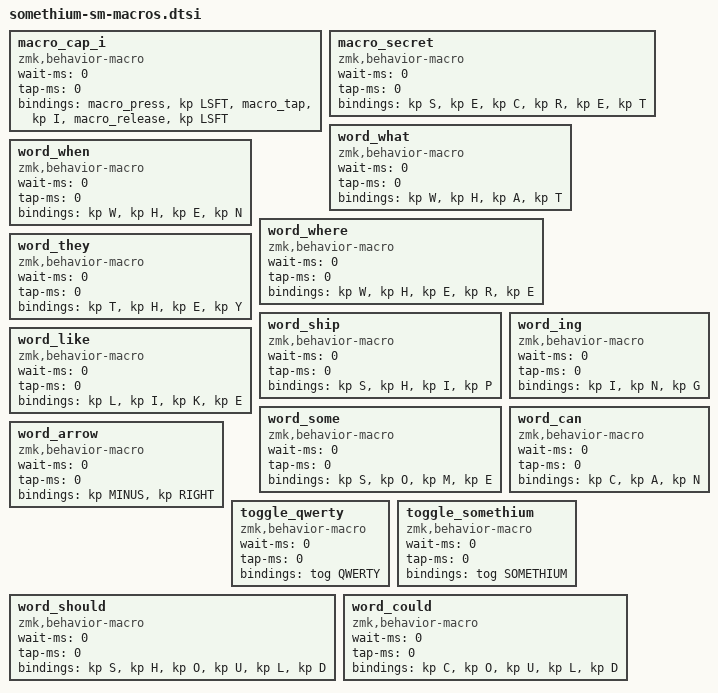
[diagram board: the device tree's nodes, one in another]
/*
 * Somethium word/toggle macros (included in main macros { }).
 */

        macro_cap_i: macro_cap_i {
            compatible = "zmk,behavior-macro";
            #binding-cells = <0>;
            wait-ms = <0>;
            tap-ms = <0>;
            bindings
                = <&macro_press &kp LSFT>
                , <&macro_tap &kp I>
                , <&macro_release &kp LSFT>
                ;
        };

        macro_secret: macro_secret {
            compatible = "zmk,behavior-macro";
            #binding-cells = <0>;
            wait-ms = <0>;
            tap-ms = <0>;
            bindings = <&kp S &kp E &kp C &kp R &kp E &kp T>;
        };

        word_what: word_what {
            compatible = "zmk,behavior-macro";
            #binding-cells = <0>;
            wait-ms = <0>;
            tap-ms = <0>;
            bindings = <&kp W &kp H &kp A &kp T>;
        };

        word_when: word_when {
            compatible = "zmk,behavior-macro";
            #binding-cells = <0>;
            wait-ms = <0>;
            tap-ms = <0>;
            bindings = <&kp W &kp H &kp E &kp N>;
        };

        word_where: word_where {
            compatible = "zmk,behavior-macro";
            #binding-cells = <0>;
            wait-ms = <0>;
            tap-ms = <0>;
            bindings = <&kp W &kp H &kp E &kp R &kp E>;
        };

        word_they: word_they {
            compatible = "zmk,behavior-macro";
            #binding-cells = <0>;
            wait-ms = <0>;
            tap-ms = <0>;
            bindings = <&kp T &kp H &kp E &kp Y>;
        };

        word_ship: word_ship {
            compatible = "zmk,behavior-macro";
            #binding-cells = <0>;
            wait-ms = <0>;
            tap-ms = <0>;
            bindings = <&kp S &kp H &kp I &kp P>;
        };

        word_ing: word_ing {
            compatible = "zmk,behavior-macro";
            #binding-cells = <0>;
            wait-ms = <0>;
            tap-ms = <0>;
            bindings = <&kp I &kp N &kp G>;
        };

        word_like: word_like {
            compatible = "zmk,behavior-macro";
            #binding-cells = <0>;
            wait-ms = <0>;
            tap-ms = <0>;
            bindings = <&kp L &kp I &kp K &kp E>;
        };

        word_some: word_some {
            compatible = "zmk,behavior-macro";
            #binding-cells = <0>;
            wait-ms = <0>;
            tap-ms = <0>;
            bindings = <&kp S &kp O &kp M &kp E>;
        };

        word_can: word_can {
            compatible = "zmk,behavior-macro";
            #binding-cells = <0>;
            wait-ms = <0>;
            tap-ms = <0>;
            bindings = <&kp C &kp A &kp N>;
        };

        word_arrow: word_arrow {
            compatible = "zmk,behavior-macro";
            #binding-cells = <0>;
            wait-ms = <0>;
            tap-ms = <0>;
            bindings = <&kp MINUS &kp RIGHT>;
        };

        toggle_qwerty: toggle_qwerty {
            compatible = "zmk,behavior-macro";
            #binding-cells = <0>;
            wait-ms = <0>;
            tap-ms = <0>;
            bindings = <&tog QWERTY>;
        };

        toggle_somethium: toggle_somethium {
            compatible = "zmk,behavior-macro";
            #binding-cells = <0>;
            wait-ms = <0>;
            tap-ms = <0>;
            bindings = <&tog SOMETHIUM>;
        };

        word_should: word_should {
            compatible = "zmk,behavior-macro";
            #binding-cells = <0>;
            wait-ms = <0>;
            tap-ms = <0>;
            bindings = <&kp S &kp H &kp O &kp U &kp L &kp D>;
        };

        word_could: word_could {
            compatible = "zmk,behavior-macro";
            #binding-cells = <0>;
            wait-ms = <0>;
            tap-ms = <0>;
            bindings = <&kp C &kp O &kp U &kp L &kp D>;
        };
